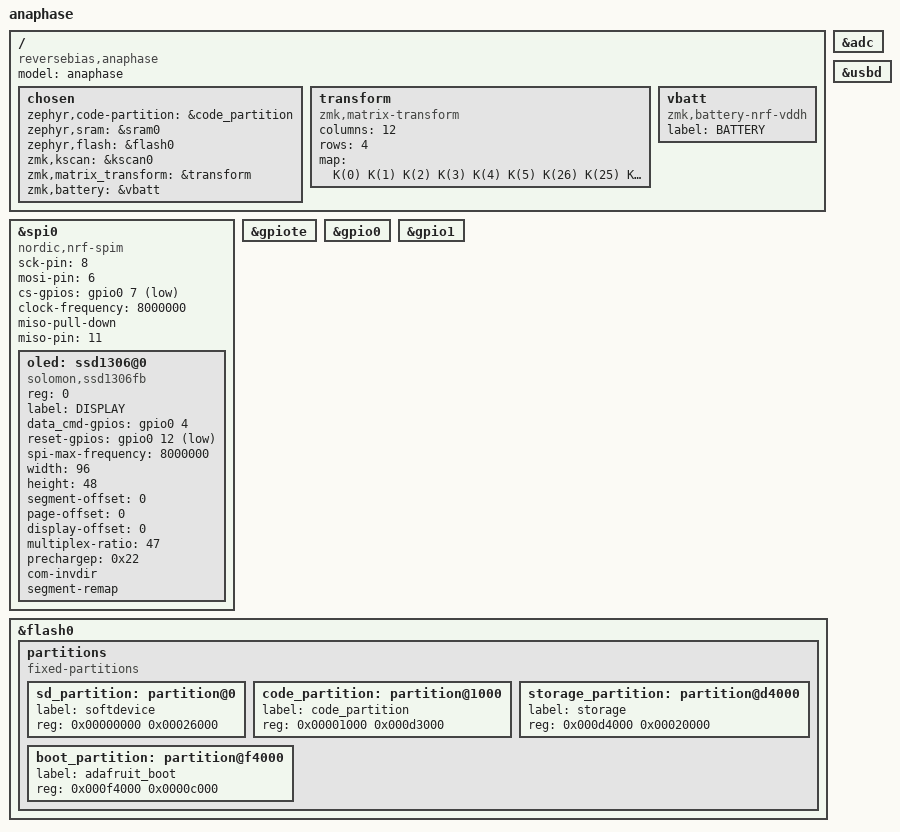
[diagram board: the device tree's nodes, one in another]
/**
 * Copyright (c) 2021
 *
 * SPDX-License-Identifier: MIT
 */

/dts-v1/;
#include <nordic/nrf52840_qiaa.dtsi>
#include <dt-bindings/zmk/matrix_transform.h>

/ {
    model = "anaphase";
    compatible = "reversebias,anaphase";

    chosen {
        zephyr,code-partition = &code_partition;
        zephyr,sram = &sram0;
        zephyr,flash = &flash0;
        zmk,kscan = &kscan0;
        zmk,matrix_transform = &transform;
        zmk,battery = &vbatt;
    };
#define K(n) RC(0,n)
    transform: transform {
        compatible = "zmk,matrix-transform";
        columns = <12>;
        rows = <4>;
        map = <
            K(0)  K(1)  K(2)  K(3)  K(4)  K(5)    K(26) K(25) K(24) K(23) K(22) K(21)
            K(6)  K(7)  K(8)  K(9)  K(10) K(11)   K(32) K(31) K(30) K(29) K(28) K(27)
            K(12) K(13) K(14) K(15) K(16) K(17)   K(38) K(37) K(36) K(35) K(34) K(33)
                              K(18) K(19) K(20)   K(41) K(40) K(39)
        >;
    };

    vbatt: vbatt {
        compatible = "zmk,battery-nrf-vddh";
        label = "BATTERY";
    };
};

&spi0 {
    compatible = "nordic,nrf-spim";
    status = "okay";
    sck-pin = <8>;
    mosi-pin = <6>;
    cs-gpios = <&gpio0 7 GPIO_ACTIVE_LOW>;
    clock-frequency = <8000000>;
    miso-pull-down;
    // unused pin, but needed by SPI definition
    miso-pin = <11>;

    oled: ssd1306@0 {
        compatible = "solomon,ssd1306fb";
        reg = <0>;
        label = "DISPLAY";
        data_cmd-gpios = <&gpio0 4 GPIO_ACTIVE_HIGH>;
        reset-gpios = <&gpio0 12 GPIO_ACTIVE_LOW>;
        spi-max-frequency = <8000000>;
        width = <96>;
        height = <48>;
        segment-offset = <0>;
        page-offset = <0>;
        display-offset = <0>;
        multiplex-ratio = <47>;
        prechargep = <0x22>;
        com-invdir;
        segment-remap;
    };
};

&adc {
    status = "okay";
};

&gpiote {
    status = "okay";
};

&gpio0 {
    status = "okay";
};

&gpio1 {
    status = "okay";
};

&usbd {
    status = "okay";
};

&flash0 {
    // For more information, see
    // https://docs.zephyrproject.org/latest/reference/storage/flash_map/flash_map.html
    partitions {
        compatible = "fixed-partitions";
        #address-cells = <1>;
        #size-cells = <1>;

        sd_partition: partition@0 {
            label = "softdevice";
            reg = <0x00000000 0x00026000>;
        };
        code_partition: partition@1000 {
            label = "code_partition";
            reg = <0x00001000 0x000d3000>;
        };

        // The flash starting at 0x000d4000 and ending at
        // 0x000f3fff is reserved for use by the application.

        // Storage partition will be used by FCB/LittleFS/NVS if enabled.
        storage_partition: partition@d4000 {
            label = "storage";
            reg = <0x000d4000 0x00020000>;
        };

        boot_partition: partition@f4000 {
            label = "adafruit_boot";
            reg = <0x000f4000 0x0000c000>;
        };
    };
};
